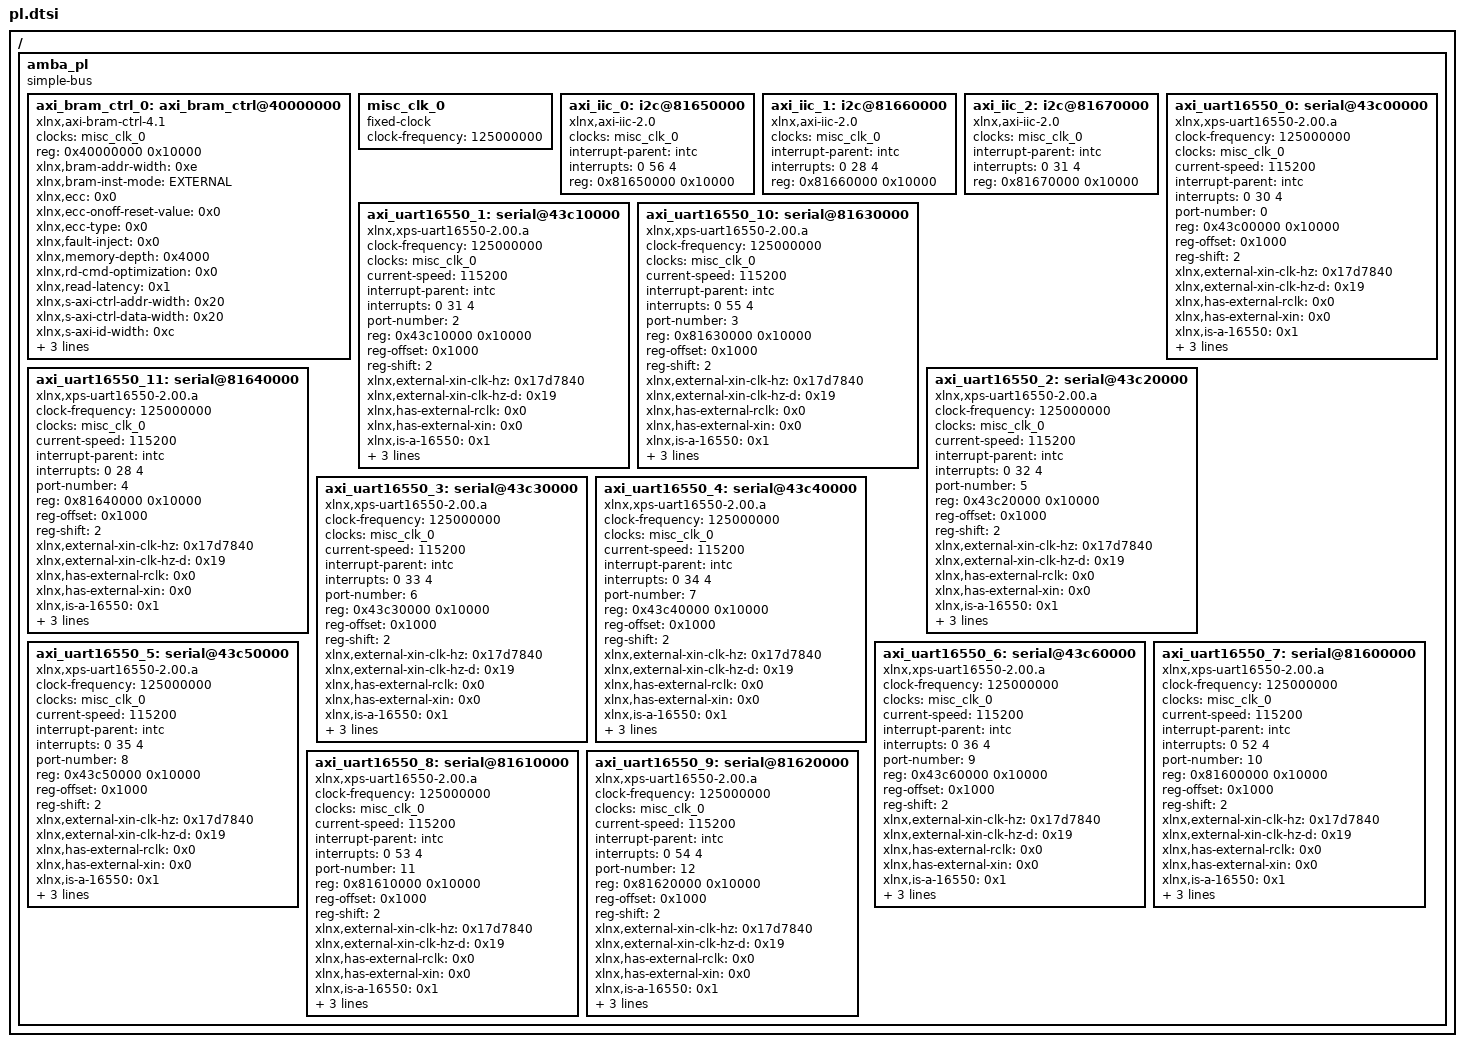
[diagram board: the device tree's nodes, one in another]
/*
 * CAUTION: This file is automatically generated by Xilinx.
 * Version: XSCT 2018.3
 * Today is: Thu Jun 18 10:42:37 2020
 */


/ {
	amba_pl: amba_pl {
		#address-cells = <1>;
		#size-cells = <1>;
		compatible = "simple-bus";
		ranges ;
		axi_bram_ctrl_0: axi_bram_ctrl@40000000 {
			/* This is a place holder node for a custom IP, user may need to update the entries */
			clock-names = "s_axi_aclk";
			clocks = <&misc_clk_0>;
			compatible = "xlnx,axi-bram-ctrl-4.1";
			reg = <0x40000000 0x10000>;
			xlnx,bram-addr-width = <0xe>;
			xlnx,bram-inst-mode = "EXTERNAL";
			xlnx,ecc = <0x0>;
			xlnx,ecc-onoff-reset-value = <0x0>;
			xlnx,ecc-type = <0x0>;
			xlnx,fault-inject = <0x0>;
			xlnx,memory-depth = <0x4000>;
			xlnx,rd-cmd-optimization = <0x0>;
			xlnx,read-latency = <0x1>;
			xlnx,s-axi-ctrl-addr-width = <0x20>;
			xlnx,s-axi-ctrl-data-width = <0x20>;
			xlnx,s-axi-id-width = <0xc>;
			xlnx,s-axi-supports-narrow-burst = <0x0>;
			xlnx,select-xpm = <0x0>;
			xlnx,single-port-bram = <0x1>;
		};
		misc_clk_0: misc_clk_0 {
			#clock-cells = <0>;
			clock-frequency = <125000000>;
			compatible = "fixed-clock";
		};
		axi_iic_0: i2c@81650000 {
			#address-cells = <1>;
			#size-cells = <0>;
			clock-names = "s_axi_aclk";
			clocks = <&misc_clk_0>;
			compatible = "xlnx,axi-iic-2.0", "xlnx,xps-iic-2.00.a";
			interrupt-names = "iic2intc_irpt";
			interrupt-parent = <&intc>;
			interrupts = <0 56 4>;
			reg = <0x81650000 0x10000>;
		};
		axi_iic_1: i2c@81660000 {
			#address-cells = <1>;
			#size-cells = <0>;
			clock-names = "s_axi_aclk";
			clocks = <&misc_clk_0>;
			compatible = "xlnx,axi-iic-2.0", "xlnx,xps-iic-2.00.a";
			interrupt-names = "iic2intc_irpt";
			interrupt-parent = <&intc>;
			interrupts = <0 28 4>;
			reg = <0x81660000 0x10000>;
		};
		axi_iic_2: i2c@81670000 {
			#address-cells = <1>;
			#size-cells = <0>;
			clock-names = "s_axi_aclk";
			clocks = <&misc_clk_0>;
			compatible = "xlnx,axi-iic-2.0", "xlnx,xps-iic-2.00.a";
			interrupt-names = "iic2intc_irpt";
			interrupt-parent = <&intc>;
			interrupts = <0 31 4>;
			reg = <0x81670000 0x10000>;
		};
		axi_uart16550_0: serial@43c00000 {
			clock-frequency = <125000000>;
			clock-names = "s_axi_aclk";
			clocks = <&misc_clk_0>;
			compatible = "xlnx,xps-uart16550-2.00.a", "ns16550a";
			current-speed = <115200>;
			device_type = "serial";
			interrupt-names = "ip2intc_irpt";
			interrupt-parent = <&intc>;
			interrupts = <0 30 4>;
			port-number = <0>;
			reg = <0x43c00000 0x10000>;
			reg-offset = <0x1000>;
			reg-shift = <2>;
			xlnx,external-xin-clk-hz = <0x17d7840>;
			xlnx,external-xin-clk-hz-d = <0x19>;
			xlnx,has-external-rclk = <0x0>;
			xlnx,has-external-xin = <0x0>;
			xlnx,is-a-16550 = <0x1>;
			xlnx,s-axi-aclk-freq-hz-d = "125.0";
			xlnx,use-modem-ports = <0x1>;
			xlnx,use-user-ports = <0x1>;
		};
		axi_uart16550_1: serial@43c10000 {
			clock-frequency = <125000000>;
			clock-names = "s_axi_aclk";
			clocks = <&misc_clk_0>;
			compatible = "xlnx,xps-uart16550-2.00.a", "ns16550a";
			current-speed = <115200>;
			device_type = "serial";
			interrupt-names = "ip2intc_irpt";
			interrupt-parent = <&intc>;
			interrupts = <0 31 4>;
			port-number = <2>;
			reg = <0x43c10000 0x10000>;
			reg-offset = <0x1000>;
			reg-shift = <2>;
			xlnx,external-xin-clk-hz = <0x17d7840>;
			xlnx,external-xin-clk-hz-d = <0x19>;
			xlnx,has-external-rclk = <0x0>;
			xlnx,has-external-xin = <0x0>;
			xlnx,is-a-16550 = <0x1>;
			xlnx,s-axi-aclk-freq-hz-d = "125.0";
			xlnx,use-modem-ports = <0x1>;
			xlnx,use-user-ports = <0x1>;
		};
		axi_uart16550_10: serial@81630000 {
			clock-frequency = <125000000>;
			clock-names = "s_axi_aclk";
			clocks = <&misc_clk_0>;
			compatible = "xlnx,xps-uart16550-2.00.a", "ns16550a";
			current-speed = <115200>;
			device_type = "serial";
			interrupt-names = "ip2intc_irpt";
			interrupt-parent = <&intc>;
			interrupts = <0 55 4>;
			port-number = <3>;
			reg = <0x81630000 0x10000>;
			reg-offset = <0x1000>;
			reg-shift = <2>;
			xlnx,external-xin-clk-hz = <0x17d7840>;
			xlnx,external-xin-clk-hz-d = <0x19>;
			xlnx,has-external-rclk = <0x0>;
			xlnx,has-external-xin = <0x0>;
			xlnx,is-a-16550 = <0x1>;
			xlnx,s-axi-aclk-freq-hz-d = "125.0";
			xlnx,use-modem-ports = <0x1>;
			xlnx,use-user-ports = <0x1>;
		};
		axi_uart16550_11: serial@81640000 {
			clock-frequency = <125000000>;
			clock-names = "s_axi_aclk";
			clocks = <&misc_clk_0>;
			compatible = "xlnx,xps-uart16550-2.00.a", "ns16550a";
			current-speed = <115200>;
			device_type = "serial";
			interrupt-names = "ip2intc_irpt";
			interrupt-parent = <&intc>;
			interrupts = <0 28 4>;
			port-number = <4>;
			reg = <0x81640000 0x10000>;
			reg-offset = <0x1000>;
			reg-shift = <2>;
			xlnx,external-xin-clk-hz = <0x17d7840>;
			xlnx,external-xin-clk-hz-d = <0x19>;
			xlnx,has-external-rclk = <0x0>;
			xlnx,has-external-xin = <0x0>;
			xlnx,is-a-16550 = <0x1>;
			xlnx,s-axi-aclk-freq-hz-d = "125.0";
			xlnx,use-modem-ports = <0x1>;
			xlnx,use-user-ports = <0x1>;
		};
		axi_uart16550_2: serial@43c20000 {
			clock-frequency = <125000000>;
			clock-names = "s_axi_aclk";
			clocks = <&misc_clk_0>;
			compatible = "xlnx,xps-uart16550-2.00.a", "ns16550a";
			current-speed = <115200>;
			device_type = "serial";
			interrupt-names = "ip2intc_irpt";
			interrupt-parent = <&intc>;
			interrupts = <0 32 4>;
			port-number = <5>;
			reg = <0x43c20000 0x10000>;
			reg-offset = <0x1000>;
			reg-shift = <2>;
			xlnx,external-xin-clk-hz = <0x17d7840>;
			xlnx,external-xin-clk-hz-d = <0x19>;
			xlnx,has-external-rclk = <0x0>;
			xlnx,has-external-xin = <0x0>;
			xlnx,is-a-16550 = <0x1>;
			xlnx,s-axi-aclk-freq-hz-d = "125.0";
			xlnx,use-modem-ports = <0x1>;
			xlnx,use-user-ports = <0x1>;
		};
		axi_uart16550_3: serial@43c30000 {
			clock-frequency = <125000000>;
			clock-names = "s_axi_aclk";
			clocks = <&misc_clk_0>;
			compatible = "xlnx,xps-uart16550-2.00.a", "ns16550a";
			current-speed = <115200>;
			device_type = "serial";
			interrupt-names = "ip2intc_irpt";
			interrupt-parent = <&intc>;
			interrupts = <0 33 4>;
			port-number = <6>;
			reg = <0x43c30000 0x10000>;
			reg-offset = <0x1000>;
			reg-shift = <2>;
			xlnx,external-xin-clk-hz = <0x17d7840>;
			xlnx,external-xin-clk-hz-d = <0x19>;
			xlnx,has-external-rclk = <0x0>;
			xlnx,has-external-xin = <0x0>;
			xlnx,is-a-16550 = <0x1>;
			xlnx,s-axi-aclk-freq-hz-d = "125.0";
			xlnx,use-modem-ports = <0x1>;
			xlnx,use-user-ports = <0x1>;
		};
		axi_uart16550_4: serial@43c40000 {
			clock-frequency = <125000000>;
			clock-names = "s_axi_aclk";
			clocks = <&misc_clk_0>;
			compatible = "xlnx,xps-uart16550-2.00.a", "ns16550a";
			current-speed = <115200>;
			device_type = "serial";
			interrupt-names = "ip2intc_irpt";
			interrupt-parent = <&intc>;
			interrupts = <0 34 4>;
			port-number = <7>;
			reg = <0x43c40000 0x10000>;
			reg-offset = <0x1000>;
			reg-shift = <2>;
			xlnx,external-xin-clk-hz = <0x17d7840>;
			xlnx,external-xin-clk-hz-d = <0x19>;
			xlnx,has-external-rclk = <0x0>;
			xlnx,has-external-xin = <0x0>;
			xlnx,is-a-16550 = <0x1>;
			xlnx,s-axi-aclk-freq-hz-d = "125.0";
			xlnx,use-modem-ports = <0x1>;
			xlnx,use-user-ports = <0x1>;
		};
		axi_uart16550_5: serial@43c50000 {
			clock-frequency = <125000000>;
			clock-names = "s_axi_aclk";
			clocks = <&misc_clk_0>;
			compatible = "xlnx,xps-uart16550-2.00.a", "ns16550a";
			current-speed = <115200>;
			device_type = "serial";
			interrupt-names = "ip2intc_irpt";
			interrupt-parent = <&intc>;
			interrupts = <0 35 4>;
			port-number = <8>;
			reg = <0x43c50000 0x10000>;
			reg-offset = <0x1000>;
			reg-shift = <2>;
			xlnx,external-xin-clk-hz = <0x17d7840>;
			xlnx,external-xin-clk-hz-d = <0x19>;
			xlnx,has-external-rclk = <0x0>;
			xlnx,has-external-xin = <0x0>;
			xlnx,is-a-16550 = <0x1>;
			xlnx,s-axi-aclk-freq-hz-d = "125.0";
			xlnx,use-modem-ports = <0x1>;
			xlnx,use-user-ports = <0x1>;
		};
		axi_uart16550_6: serial@43c60000 {
			clock-frequency = <125000000>;
			clock-names = "s_axi_aclk";
			clocks = <&misc_clk_0>;
			compatible = "xlnx,xps-uart16550-2.00.a", "ns16550a";
			current-speed = <115200>;
			device_type = "serial";
			interrupt-names = "ip2intc_irpt";
			interrupt-parent = <&intc>;
			interrupts = <0 36 4>;
			port-number = <9>;
			reg = <0x43c60000 0x10000>;
			reg-offset = <0x1000>;
			reg-shift = <2>;
			xlnx,external-xin-clk-hz = <0x17d7840>;
			xlnx,external-xin-clk-hz-d = <0x19>;
			xlnx,has-external-rclk = <0x0>;
			xlnx,has-external-xin = <0x0>;
			xlnx,is-a-16550 = <0x1>;
			xlnx,s-axi-aclk-freq-hz-d = "125.0";
			xlnx,use-modem-ports = <0x1>;
			xlnx,use-user-ports = <0x1>;
		};
		axi_uart16550_7: serial@81600000 {
			clock-frequency = <125000000>;
			clock-names = "s_axi_aclk";
			clocks = <&misc_clk_0>;
			compatible = "xlnx,xps-uart16550-2.00.a", "ns16550a";
			current-speed = <115200>;
			device_type = "serial";
			interrupt-names = "ip2intc_irpt";
			interrupt-parent = <&intc>;
			interrupts = <0 52 4>;
			port-number = <10>;
			reg = <0x81600000 0x10000>;
			reg-offset = <0x1000>;
			reg-shift = <2>;
			xlnx,external-xin-clk-hz = <0x17d7840>;
			xlnx,external-xin-clk-hz-d = <0x19>;
			xlnx,has-external-rclk = <0x0>;
			xlnx,has-external-xin = <0x0>;
			xlnx,is-a-16550 = <0x1>;
			xlnx,s-axi-aclk-freq-hz-d = "125.0";
			xlnx,use-modem-ports = <0x1>;
			xlnx,use-user-ports = <0x1>;
		};
		axi_uart16550_8: serial@81610000 {
			clock-frequency = <125000000>;
			clock-names = "s_axi_aclk";
			clocks = <&misc_clk_0>;
			compatible = "xlnx,xps-uart16550-2.00.a", "ns16550a";
			current-speed = <115200>;
			device_type = "serial";
			interrupt-names = "ip2intc_irpt";
			interrupt-parent = <&intc>;
			interrupts = <0 53 4>;
			port-number = <11>;
			reg = <0x81610000 0x10000>;
			reg-offset = <0x1000>;
			reg-shift = <2>;
			xlnx,external-xin-clk-hz = <0x17d7840>;
			xlnx,external-xin-clk-hz-d = <0x19>;
			xlnx,has-external-rclk = <0x0>;
			xlnx,has-external-xin = <0x0>;
			xlnx,is-a-16550 = <0x1>;
			xlnx,s-axi-aclk-freq-hz-d = "125.0";
			xlnx,use-modem-ports = <0x1>;
			xlnx,use-user-ports = <0x1>;
		};
		axi_uart16550_9: serial@81620000 {
			clock-frequency = <125000000>;
			clock-names = "s_axi_aclk";
			clocks = <&misc_clk_0>;
			compatible = "xlnx,xps-uart16550-2.00.a", "ns16550a";
			current-speed = <115200>;
			device_type = "serial";
			interrupt-names = "ip2intc_irpt";
			interrupt-parent = <&intc>;
			interrupts = <0 54 4>;
			port-number = <12>;
			reg = <0x81620000 0x10000>;
			reg-offset = <0x1000>;
			reg-shift = <2>;
			xlnx,external-xin-clk-hz = <0x17d7840>;
			xlnx,external-xin-clk-hz-d = <0x19>;
			xlnx,has-external-rclk = <0x0>;
			xlnx,has-external-xin = <0x0>;
			xlnx,is-a-16550 = <0x1>;
			xlnx,s-axi-aclk-freq-hz-d = "125.0";
			xlnx,use-modem-ports = <0x1>;
			xlnx,use-user-ports = <0x1>;
		};
	};
};
